# renode register map
Vendor: litex
Registers are 32-bit, read-write, reset 0x0 unless marked. A register's access mark holds for its fields unless they carry their own. Offsets are from the block's base; [hi:lo] are bit positions.

## ENGINE
Base 0xF001E000
0x00 WINDOW
  [3:0] window — Selects the current register window to use
0x04 MPSTART
  [9:0] mpstart — Where to start execution
0x08 MPLEN
  [9:0] mplen — Length of the current microcode program. Thus valid code must be in the range of [mpstart, mpstart + mplen]
0x0C CONTROL
  [0] go — Writing to this puts the engine in `run` mode, and it will execute mplen microcode instructions starting at mpstart
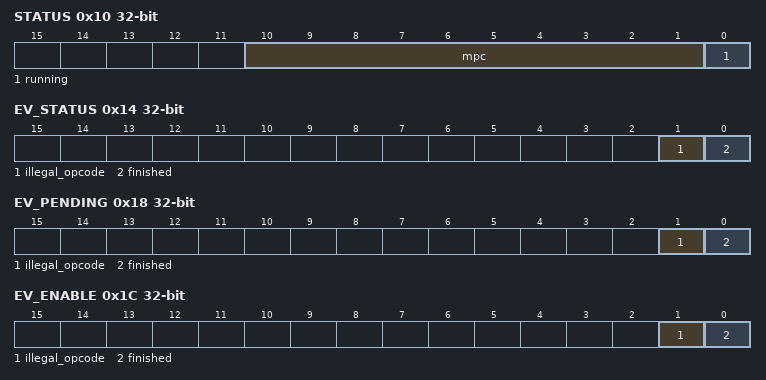
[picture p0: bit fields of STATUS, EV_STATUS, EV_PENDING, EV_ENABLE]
0x10 STATUS
  [10:1] mpc — Current location of the microcode program counter. Mostly for debug.
  [0] running — When set, the microcode engine is running. All wishbone access to RF and microcode memory areas will stall until this bit is clear
0x14 EV_STATUS — Illegal opcode encountered
  [1] illegal_opcode — Level of the ``illegal_opcode`` event
  [0] finished — Level of the ``finished`` event
0x18 EV_PENDING — Illegal opcode encountered
  [1] illegal_opcode — Illegal opcode encountered
  [0] finished — Microcode run finished execution
0x1C EV_ENABLE — Illegal opcode encountered
  [1] illegal_opcode — Write a ``1`` to enable the ``illegal_opcode`` Event
  [0] finished — Write a ``1`` to enable the ``finished`` Event
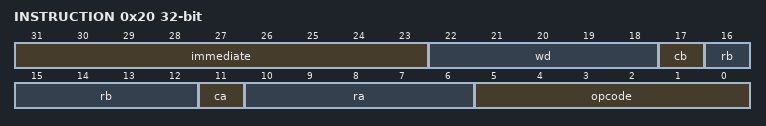
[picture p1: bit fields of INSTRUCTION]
0x20 INSTRUCTION — Current instruction being executed by the engine. The format of this register exactly reflects the binary layout of an Engine instruction.
  [31:23] immediate — Used by jumps to load the next PC value
  [22:18] wd — write register
  [17] cb — set to substitute constant table value for B
  [16:12] rb — operand B read register
  [11] ca — set to substitute constant table value for A
  [10:6] ra — operand A read register
  [5:0] opcode — opcode to be executed

## JTAG
Base 0xF001F000
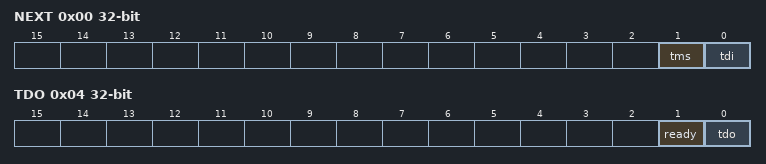
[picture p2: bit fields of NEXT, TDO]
0x00 NEXT — Next state for TDI/TMS; writing automatically clocks TCK
  [1] tms — TMS pin value
  [0] tdi — TDI pin value
0x04 TDO — TDO resulting from previous cycle
  [1] ready — JTAG machine is ready for a new cycle; also indicates TDO is valid
  [0] tdo — TDO pin value

## WDT
Base 0xF0020000
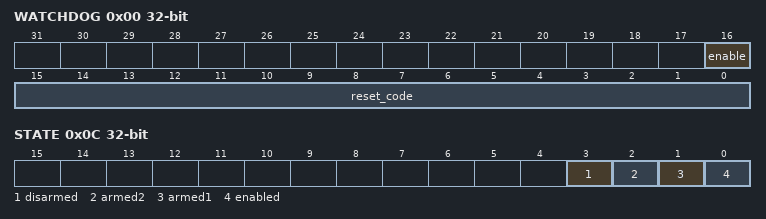
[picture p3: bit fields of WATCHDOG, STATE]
0x00 WATCHDOG
  [16] enable — Enable the watchdog timer. Cannot be disabled once enabled, except with a reset. Notably, a watchdog reset will disable the watchdog.
  [15:0] reset_code — Write `600d` then `c0de` in sequence to this register to reset the watchdog timer
0x04 PERIOD reset 0x135F1B40
  [31:0] period — Number of 'approximately 65MHz' CFGMCLK cycles before each reset_code must be entered. Defaults to a range of 1.67-5.00 seconds
0x08 INTERRUPT
  [0] interrupt — Writing this causes an interrupt to fire. Used by the kernel to initiate a routine to reset the WDT in an interrupt context.
0x0C STATE
  [3] disarmed — WDT in the disarmed state
  [2] armed2 — WDT in the armed2 state
  [1] armed1 — WDT in the armed1 state
  [0] enabled — WDT has been enabled
0x10 EV_STATUS — This register contains the current raw level of the soft_int event trigger. Writes to this register have no effect.
  [0] soft_int — Level of the ``soft_int`` event
0x14 EV_PENDING — When a soft_int event occurs, the corresponding bit will be set in this register. To clear the Event, set the corresponding bit in this register.
  [0] soft_int — `1` if a `soft_int` event occurred. This Event is triggered on a **falling** edge.
0x18 EV_ENABLE — This register enables the corresponding soft_int events. Write a ``0`` to this register to disable individual events.
  [0] soft_int — Write a ``1`` to enable the ``soft_int`` Event

## D11CTIME
Base 0xF0021000
0x00 CONTROL reset 0x666
  [14:0] count — Number of 1/32768 second ticks before creating a heart beat
0x04 HEARTBEAT
  [0] beat — Set to `1` at the next `count` interval rollover since `clear` was set.

## IDENTIFIER_MEM
Base 0xF0022000
0x00 IDENTIFIER_MEM — 8 x 19-bit memory
  [7:0] identifier_mem

## TIMER0
Base 0xF0023000
0x00 LOAD — Load value when Timer is (re-)enabled. In One-Shot mode, the value written to this register specifies the Timer's duration in clock cycles.
0x04 RELOAD — Reload value when Timer reaches ``0``. In Periodic mode, the value written to this register specify the Timer's period in clock cycles.
0x08 EN — Enable flag of the Timer. Set this flag to ``1`` to enable/start the Timer. Set to ``0`` to disable the Timer.
  [0] en
0x0C UPDATE_VALUE — Update trigger for the current countdown value. A write to this register latches the current countdown value to ``value`` register.
  [0] update_value
0x10 VALUE — Latched countdown value. This value is updated by writing to ``update_value``.
0x14 EV_STATUS — This register contains the current raw level of the zero event trigger. Writes to this register have no effect.
  [0] zero — Level of the ``zero`` event
0x18 EV_PENDING — When a zero event occurs, the corresponding bit will be set in this register. To clear the Event, set the corresponding bit in this register.
  [0] zero — `1` if a `zero` event occurred. This Event is triggered on a **falling** edge.
0x1C EV_ENABLE — This register enables the corresponding zero events. Write a ``0`` to this register to disable individual events.
  [0] zero — Write a ``1`` to enable the ``zero`` Event
